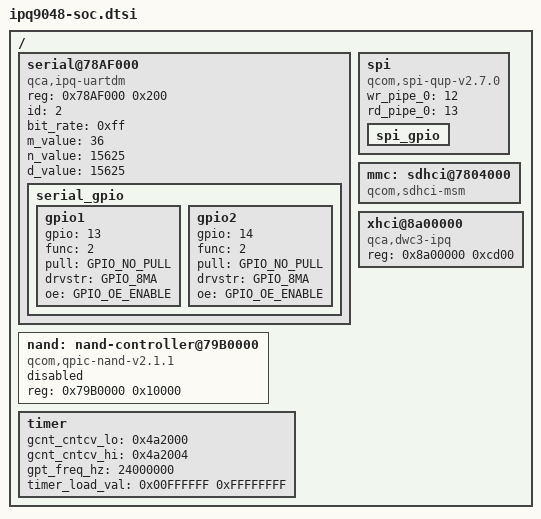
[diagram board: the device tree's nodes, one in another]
/*
 * Copyright (c) 2016-2020, The Linux Foundation. All rights reserved.
 *
 * This program is free software; you can redistribute it and/or modify
 * it under the terms of the GNU General Public License version 2 and
 * only version 2 as published by the Free Software Foundation.
 *
 * This program is distributed in the hope that it will be useful,
 * but WITHOUT ANY WARRANTY; without even the implied warranty of
 * MERCHANTABILITY or FITNESS FOR A PARTICULAR PURPOSE.  See the
 * GNU General Public License for more details.
 */

#include "skeleton.dtsi"
#include <dt-bindings/qcom/gpio-ipq9048.h>

/ {

	serial@78AF000 {
		compatible = "qca,ipq-uartdm";
		reg = <0x78AF000 0x200>;
		id = <2>;
		bit_rate = <0xff>;
		status = "ok";
		m_value = <36>;
		n_value = <15625>;
		d_value = <15625>;
		serial_gpio {
			gpio1 {
				gpio = <13>;
				func = <2>;
				pull = <GPIO_NO_PULL>;
				drvstr = <GPIO_8MA>;
				oe = <GPIO_OE_ENABLE>;
			};

			gpio2 {
				gpio = <14>;
				func = <2>;
				pull = <GPIO_NO_PULL>;
				drvstr = <GPIO_8MA>;
				oe = <GPIO_OE_ENABLE>;
			};
		};
	};

	spi {
		status = "ok";

		compatible = "qcom,spi-qup-v2.7.0";
		wr_pipe_0 = <12>;
		rd_pipe_0 = <13>;
		spi_gpio {
		};
	};

	nand: nand-controller@79B0000 {
		#address-cells = <1>;
		#size-cells = <0>;
		compatible = "qcom,qpic-nand-v2.1.1";
		reg = <0x79B0000 0x10000>;
		status = "disabled";
	};

	mmc: sdhci@7804000 {
		compatible = "qcom,sdhci-msm";
	};

	xhci@8a00000 {
		compatible = "qca,dwc3-ipq";
		#address-cells = <1>;
		#size-cells = <1>;
		reg = <0x8a00000 0xcd00>;
	};

	timer {
		gcnt_cntcv_lo = <0x4a2000>;
		gcnt_cntcv_hi = <0x4a2004>;
		gpt_freq_hz = <24000000>;
		timer_load_val = <0x00FFFFFF 0xFFFFFFFF>;
	};
};

